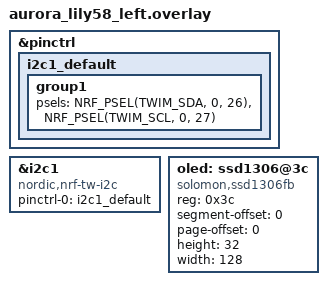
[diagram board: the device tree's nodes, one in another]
&pinctrl {
    i2c1_default: i2c1_default {
        group1 {
            psels = <NRF_PSEL(TWIM_SDA, 0, 26)>, <NRF_PSEL(TWIM_SCL, 0, 27)>;
        };
    };
};

&i2c1 {
    compatible = "nordic,nrf-tw-i2c";
    status = "okay";
    pinctrl-0 = <&i2c1_default>;
    pinctrl-names = "default";
};

oled: ssd1306@3c {
    compatible = "solomon,ssd1306fb";
    reg = <0x3c>;
    segment-offset = <0>;
    page-offset = <0>;
    height = <32>;
    width = <128>;
};
